AUTOSAR XML (schema 00044)
package /E40_Platform_System_SystemPackage/Components
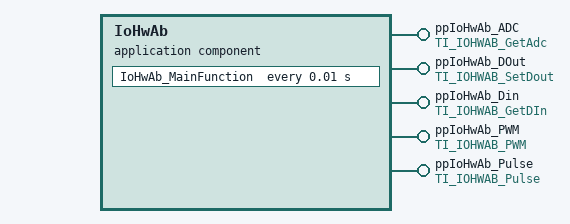
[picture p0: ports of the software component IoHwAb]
  application sw component type IoHwAb
    5 x provide port:
      ppIoHwAb_ADC: provided-interface=TI_IOHWAB_GetAdc
        provided-com-specs:
          operation=GetAsyncRawAdc, queue-length=1
          operation=GetProcessedAdc, queue-length=1
          operation=GetSyncRawAdc, queue-length=1
      ppIoHwAb_DOut: provided-com-specs=[{operation=SetOutputGroup, queue-length=1}, {operation=SetOutputPin, queue-length=1}], provided-interface=TI_IOHWAB_SetDout
      ppIoHwAb_Din: provided-interface=TI_IOHWAB_GetDIn
        provided-com-specs:
          operation=GetAsyncRawInput, queue-length=1
          operation=GetInputGroup, queue-length=1
          operation=GetProcessedInput, queue-length=1
          operation=GetSyncRawInput, queue-length=1
      ppIoHwAb_PWM: provided-interface=TI_IOHWAB_PWM
        provided-com-specs:
          operation=PwmSetDuty, queue-length=1
          operation=PwmSetDutyAndPeriod, queue-length=1
          operation=PwmSetIdeal, queue-length=1
      ppIoHwAb_Pulse: provided-interface=TI_IOHWAB_Pulse
        provided-com-specs:
          operation=GetCurrentSignalStatus_PulseInput, queue-length=1
          operation=GetCurrentSpeed_PulseInput, queue-length=1
          operation=GetRollingCount_PulseInput, queue-length=1
          operation=ResetRollingCount_PulseInput, queue-length=1
          operation=Start_Signal_Measurement_PulseInput, queue-length=1
          operation=Stop_Signal_Measurement_PulseInput, queue-length=1
          operation=Update_CalibParam_PulseInput, queue-length=1
    behavior IB_IoHwAb
      10 x operation invoked event:
        OIE_ppIoHwAb_ADC_IoHwAb_GetAsyncRawAdcTrigByGetAsyncRawAdc: start-on-event=IoHwAb_GetAsyncRawAdc, operation=ppIoHwAb_ADC.GetAsyncRawAdc
        OIE_ppIoHwAb_Din_IoHwAb_GetAsyncRawInputTrigByGetAsyncRawInput: start-on-event=IoHwAb_GetAsyncRawInput, operation=ppIoHwAb_Din.GetAsyncRawInput
        OIE_ppIoHwAb_Pulse_IoHwAb_GetCurrentSignalStatus_PulseInputTrigByGetCurrentSignalStatus_PulseInput: start-on-event=IoHwAb_GetCurrentSignalStatus_PulseInput, operation=ppIoHwAb_Pulse.GetCurrentSignalStatus_PulseInput
        OIE_ppIoHwAb_Pulse_IoHwAb_GetCurrentSpeed_PulseInputTrigByGetCurrentSpeed_PulseInput: start-on-event=IoHwAb_GetCurrentSpeed_PulseInput, operation=ppIoHwAb_Pulse.GetCurrentSpeed_PulseInput
        OIE_ppIoHwAb_Din_IoHwAb_GetInputGroupTrigByGetInputGroup: start-on-event=IoHwAb_GetInputGroup, operation=ppIoHwAb_Din.GetInputGroup
        OIE_ppIoHwAb_ADC_IoHwAb_GetProcessedAdcTrigByGetProcessedAdc: start-on-event=IoHwAb_GetProcessedAdc, operation=ppIoHwAb_ADC.GetProcessedAdc
        OIE_ppIoHwAb_Din_IoHwAb_GetProcessedInputTrigByGetProcessedInput: start-on-event=IoHwAb_GetProcessedInput, operation=ppIoHwAb_Din.GetProcessedInput
        OIE_ppIoHwAb_Pulse_IoHwAb_GetRollingCount_PulseInputTrigByGetRollingCount_PulseInput: start-on-event=IoHwAb_GetRollingCount_PulseInput, operation=ppIoHwAb_Pulse.GetRollingCount_PulseInput
        OIE_ppIoHwAb_ADC_IoHwAb_GetSyncRawAdcTrigByGetSyncRawAdc: start-on-event=IoHwAb_GetSyncRawAdc, operation=ppIoHwAb_ADC.GetSyncRawAdc
        OIE_ppIoHwAb_Din_IoHwAb_GetSyncRawInputTrigByGetSyncRawInput: start-on-event=IoHwAb_GetSyncRawInput, operation=ppIoHwAb_Din.GetSyncRawInput
      timing event TEIoHwAb_MainFunction: start-on-event=IoHwAb_MainFunction, period=0.01
      9 x operation invoked event:
        OIE_ppIoHwAb_PWM_IoHwAb_PwmSetDutyTrigByPwmSetDuty: start-on-event=IoHwAb_PwmSetDuty, operation=ppIoHwAb_PWM.PwmSetDuty
        OIE_ppIoHwAb_PWM_IoHwAb_PwmSetDutyAndPeriodTrigByPwmSetDutyAndPeriod: start-on-event=IoHwAb_PwmSetDutyAndPeriod, operation=ppIoHwAb_PWM.PwmSetDutyAndPeriod
        OIE_ppIoHwAb_PWM_IoHwAb_PwmSetIdealTrigByPwmSetIdeal: start-on-event=IoHwAb_PwmSetIdeal, operation=ppIoHwAb_PWM.PwmSetIdeal
        OIE_ppIoHwAb_Pulse_IoHwAb_ResetRollingCount_PulseInputTrigByResetRollingCount_PulseInput: start-on-event=IoHwAb_ResetRollingCount_PulseInput, operation=ppIoHwAb_Pulse.ResetRollingCount_PulseInput
        OIE_ppIoHwAb_DOut_IoHwAb_SetOutputGroupTrigBySetOutputGroup: start-on-event=IoHwAb_SetOutputGroup, operation=ppIoHwAb_DOut.SetOutputGroup
        OIE_ppIoHwAb_DOut_IoHwAb_SetOutputPinTrigBySetOutputPin: start-on-event=IoHwAb_SetOutputPin, operation=ppIoHwAb_DOut.SetOutputPin
        OIE_ppIoHwAb_Pulse_IoHwAb_Start_Signal_Measurement_PulseInputTrigByStart_Signal_Measurement_PulseInput: start-on-event=IoHwAb_Start_Signal_Measurement_PulseInput, operation=ppIoHwAb_Pulse.Start_Signal_Measurement_PulseInput
        OIE_ppIoHwAb_Pulse_IoHwAb_Stop_Signal_Measurement_PulseInputTrigByStop_Signal_Measurement_PulseInput: start-on-event=IoHwAb_Stop_Signal_Measurement_PulseInput, operation=ppIoHwAb_Pulse.Stop_Signal_Measurement_PulseInput
        OIE_ppIoHwAb_Pulse_IoHwAb_Update_CalibParam_PulseInputTrigByUpdate_CalibParam_PulseInput: start-on-event=IoHwAb_Update_CalibParam_PulseInput, operation=ppIoHwAb_Pulse.Update_CalibParam_PulseInput
      4 x timing event:
        TEIoHwAb_OsTask_SafeBsw_Task_10ms: start-on-event=IoHwAb_OsTask_SafeBsw_Task_10ms, period=0.01
        TEIoHwAb_OsTask_SafeBsw_WdgM_CheckPoint_10ms: start-on-event=IoHwAb_OsTask_SafeBsw_WdgM_CheckPoint_10ms, period=0.01
        TEIoHwAb_OsTask_SafeBsw_WdgM_CheckPoint_20ms: start-on-event=IoHwAb_OsTask_SafeBsw_WdgM_CheckPoint_20ms, period=0.02
        TEIoHwAb_OsTask_SafeBsw_WdgM_CheckPoint_30ms: start-on-event=IoHwAb_OsTask_SafeBsw_WdgM_CheckPoint_30ms, period=0.03
      port-api-options:
        enable-take-address=false, indirect-api=false, port=ppIoHwAb_ADC
        enable-take-address=false, indirect-api=false, port=ppIoHwAb_DOut
        enable-take-address=false, indirect-api=false, port=ppIoHwAb_Din
        enable-take-address=false, indirect-api=false, port=ppIoHwAb_PWM
        enable-take-address=false, indirect-api=false, port=ppIoHwAb_Pulse
      24 x runnable, all with can-be-invoked-concurrently=true:
        IoHwAb_GetAsyncRawAdc
        IoHwAb_GetAsyncRawInput
        IoHwAb_GetCurrentSignalStatus_PulseInput
        IoHwAb_GetCurrentSpeed_PulseInput
        IoHwAb_GetInputGroup
        IoHwAb_GetProcessedAdc
        IoHwAb_GetProcessedInput
        IoHwAb_GetRollingCount_PulseInput
        IoHwAb_GetSyncRawAdc
        IoHwAb_GetSyncRawInput
        IoHwAb_MainFunction
        IoHwAb_PwmSetDuty
        IoHwAb_PwmSetDutyAndPeriod
        IoHwAb_PwmSetIdeal
        IoHwAb_ResetRollingCount_PulseInput
        IoHwAb_SetOutputGroup
        IoHwAb_SetOutputPin
        IoHwAb_Start_Signal_Measurement_PulseInput
        IoHwAb_Stop_Signal_Measurement_PulseInput
        IoHwAb_Update_CalibParam_PulseInput
        IoHwAb_OsTask_SafeBsw_Task_10ms
        IoHwAb_OsTask_SafeBsw_WdgM_CheckPoint_10ms
        IoHwAb_OsTask_SafeBsw_WdgM_CheckPoint_20ms
        IoHwAb_OsTask_SafeBsw_WdgM_CheckPoint_30ms
  swc implementation IMPL_IoHwAb: behavior=IB_IoHwAb
